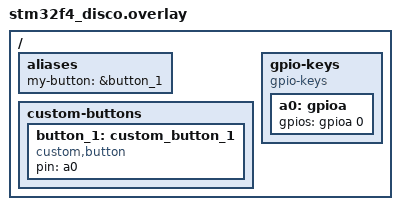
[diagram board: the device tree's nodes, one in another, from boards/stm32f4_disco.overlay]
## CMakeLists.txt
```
cmake_minimum_required(VERSION 3.20.0)

set(BOARD stm32f4_disco)
set(DTC_OVERLAY_FILE "boards/stm32f4_disco.overlay")
set(ZEPHYR_EXTRA_MODULES "${CMAKE_SOURCE_DIR}/../modules/button")

find_package(Zephyr REQUIRED HINTS $ENV{ZEPHYR_BASE})
project(custom_button)

target_sources(app PRIVATE src/main.c)
```

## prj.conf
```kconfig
CONFIG_CUSTOM_BUTTON=y
CONFIG_LOG=y
CONFIG_LOG_DEFAULT_LEVEL=4
CONFIG_GPIO=y
```

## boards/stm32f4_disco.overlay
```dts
/ {
    aliases {
	my-button = &button_1;
    };

    custom-buttons {
	button_1: custom_button_1 {
	    compatible = "custom,button";
	    pin = <&a0>;
	};
    };

    gpio-keys {
	compatible = "gpio-keys";

	a0: gpioa {
	    gpios = <&gpioa 0 GPIO_ACTIVE_HIGH>;
	};
    };
};
```

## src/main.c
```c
#include <stdint.h>
#include <stdio.h>
#include <zephyr/kernel.h>

#include "button.h"

#define SLEEP_TIME_MS 50
static const struct device *btn = DEVICE_DT_GET(DT_ALIAS(my_button));

int main(void)
{
    int ret;
    int8_t state;

    if (!device_is_ready(btn)) {
	printk("Error: buttons are not ready\r\n");
	return 0;
    }

    const struct button_api *btn_api = (const struct button_api *)btn->api;

    while(1) {
	ret = btn_api->get(btn, &state);
	if (ret < 0) {
	    printk("Error (%d): failed to read button", ret);
	    continue;
	}
	printk("state: %u\r\n", state);

	k_msleep(SLEEP_TIME_MS);
    }

    return 0;
}
```
